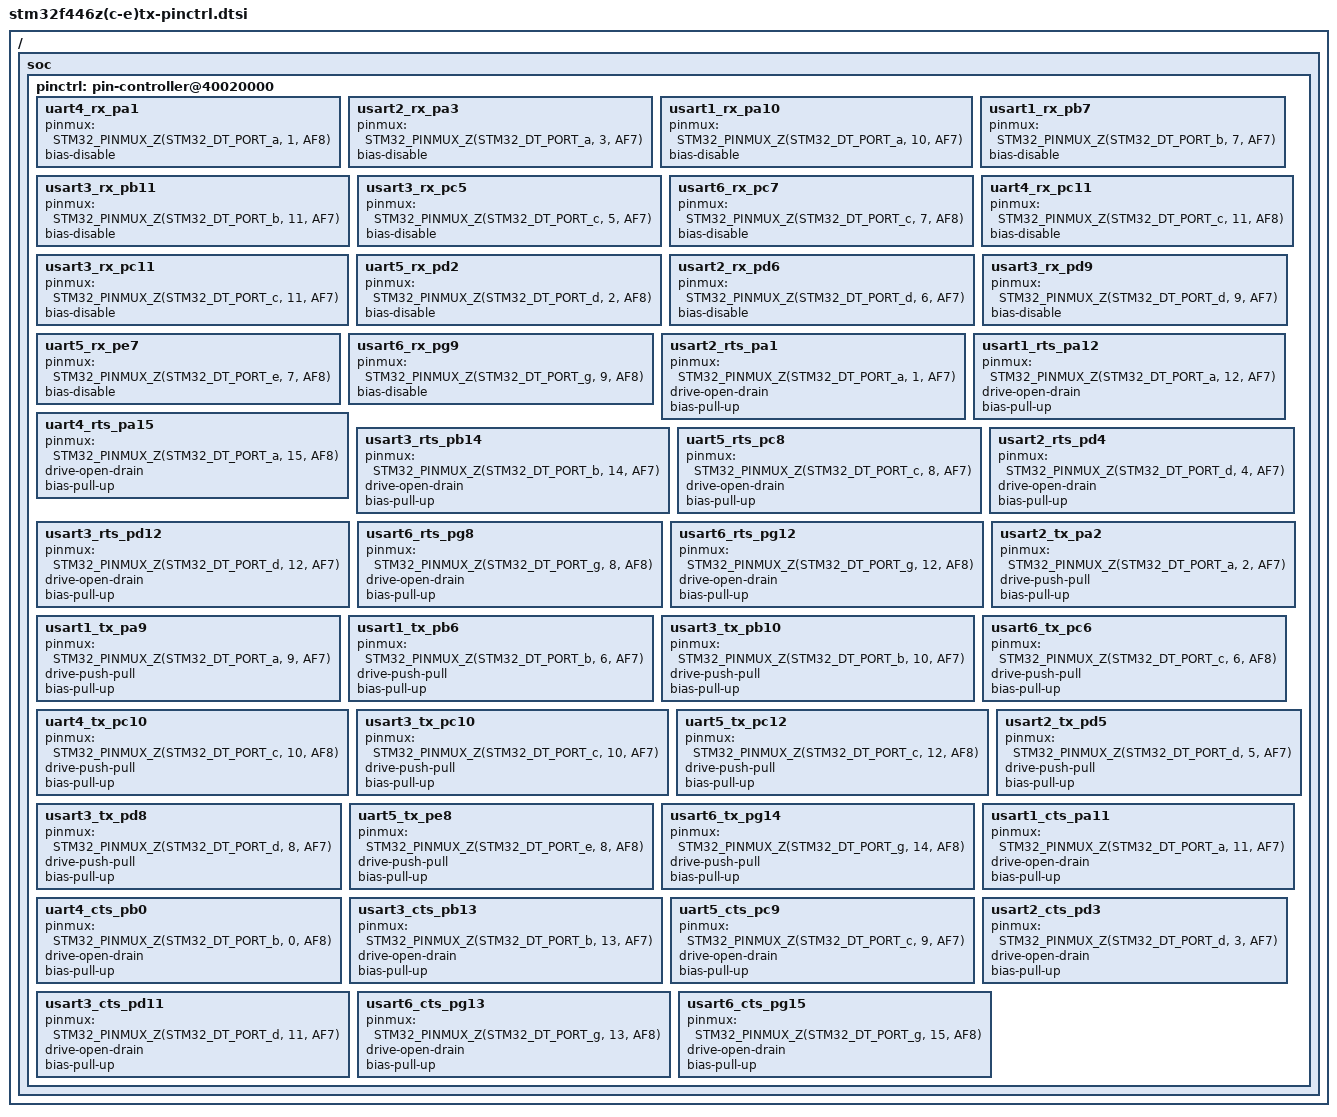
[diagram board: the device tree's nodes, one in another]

/*
 * NOTE: Autogenerated file using stm32_pinctrl_gen.py
 *
 * SPDX-License-Identifier: Apache-2.0
 */

#include <dt-bindings/pinctrl/stm32-pinctrl.h>

/ {
	soc {
		pinctrl: pin-controller@40020000 {
			/* UART_RX */
			uart4_rx_pa1: uart4_rx_pa1 {
				pinmux = <STM32_PINMUX_Z(STM32_DT_PORT_a, 1, AF8)>;
				bias-disable;
			};

			usart2_rx_pa3: usart2_rx_pa3 {
				pinmux = <STM32_PINMUX_Z(STM32_DT_PORT_a, 3, AF7)>;
				bias-disable;
			};

			usart1_rx_pa10: usart1_rx_pa10 {
				pinmux = <STM32_PINMUX_Z(STM32_DT_PORT_a, 10, AF7)>;
				bias-disable;
			};

			usart1_rx_pb7: usart1_rx_pb7 {
				pinmux = <STM32_PINMUX_Z(STM32_DT_PORT_b, 7, AF7)>;
				bias-disable;
			};

			usart3_rx_pb11: usart3_rx_pb11 {
				pinmux = <STM32_PINMUX_Z(STM32_DT_PORT_b, 11, AF7)>;
				bias-disable;
			};

			usart3_rx_pc5: usart3_rx_pc5 {
				pinmux = <STM32_PINMUX_Z(STM32_DT_PORT_c, 5, AF7)>;
				bias-disable;
			};

			usart6_rx_pc7: usart6_rx_pc7 {
				pinmux = <STM32_PINMUX_Z(STM32_DT_PORT_c, 7, AF8)>;
				bias-disable;
			};

			uart4_rx_pc11: uart4_rx_pc11 {
				pinmux = <STM32_PINMUX_Z(STM32_DT_PORT_c, 11, AF8)>;
				bias-disable;
			};

			usart3_rx_pc11: usart3_rx_pc11 {
				pinmux = <STM32_PINMUX_Z(STM32_DT_PORT_c, 11, AF7)>;
				bias-disable;
			};

			uart5_rx_pd2: uart5_rx_pd2 {
				pinmux = <STM32_PINMUX_Z(STM32_DT_PORT_d, 2, AF8)>;
				bias-disable;
			};

			usart2_rx_pd6: usart2_rx_pd6 {
				pinmux = <STM32_PINMUX_Z(STM32_DT_PORT_d, 6, AF7)>;
				bias-disable;
			};

			usart3_rx_pd9: usart3_rx_pd9 {
				pinmux = <STM32_PINMUX_Z(STM32_DT_PORT_d, 9, AF7)>;
				bias-disable;
			};

			uart5_rx_pe7: uart5_rx_pe7 {
				pinmux = <STM32_PINMUX_Z(STM32_DT_PORT_e, 7, AF8)>;
				bias-disable;
			};

			usart6_rx_pg9: usart6_rx_pg9 {
				pinmux = <STM32_PINMUX_Z(STM32_DT_PORT_g, 9, AF8)>;
				bias-disable;
			};


			/* UART_RTS */
			usart2_rts_pa1: usart2_rts_pa1 {
				pinmux = <STM32_PINMUX_Z(STM32_DT_PORT_a, 1, AF7)>;
				drive-open-drain;
				bias-pull-up;
			};

			usart1_rts_pa12: usart1_rts_pa12 {
				pinmux = <STM32_PINMUX_Z(STM32_DT_PORT_a, 12, AF7)>;
				drive-open-drain;
				bias-pull-up;
			};

			uart4_rts_pa15: uart4_rts_pa15 {
				pinmux = <STM32_PINMUX_Z(STM32_DT_PORT_a, 15, AF8)>;
				drive-open-drain;
				bias-pull-up;
			};

			usart3_rts_pb14: usart3_rts_pb14 {
				pinmux = <STM32_PINMUX_Z(STM32_DT_PORT_b, 14, AF7)>;
				drive-open-drain;
				bias-pull-up;
			};

			uart5_rts_pc8: uart5_rts_pc8 {
				pinmux = <STM32_PINMUX_Z(STM32_DT_PORT_c, 8, AF7)>;
				drive-open-drain;
				bias-pull-up;
			};

			usart2_rts_pd4: usart2_rts_pd4 {
				pinmux = <STM32_PINMUX_Z(STM32_DT_PORT_d, 4, AF7)>;
				drive-open-drain;
				bias-pull-up;
			};

			usart3_rts_pd12: usart3_rts_pd12 {
				pinmux = <STM32_PINMUX_Z(STM32_DT_PORT_d, 12, AF7)>;
				drive-open-drain;
				bias-pull-up;
			};

			usart6_rts_pg8: usart6_rts_pg8 {
				pinmux = <STM32_PINMUX_Z(STM32_DT_PORT_g, 8, AF8)>;
				drive-open-drain;
				bias-pull-up;
			};

			usart6_rts_pg12: usart6_rts_pg12 {
				pinmux = <STM32_PINMUX_Z(STM32_DT_PORT_g, 12, AF8)>;
				drive-open-drain;
				bias-pull-up;
			};


			/* UART_TX */
			usart2_tx_pa2: usart2_tx_pa2 {
				pinmux = <STM32_PINMUX_Z(STM32_DT_PORT_a, 2, AF7)>;
				drive-push-pull;
				bias-pull-up;
			};

			usart1_tx_pa9: usart1_tx_pa9 {
				pinmux = <STM32_PINMUX_Z(STM32_DT_PORT_a, 9, AF7)>;
				drive-push-pull;
				bias-pull-up;
			};

			usart1_tx_pb6: usart1_tx_pb6 {
				pinmux = <STM32_PINMUX_Z(STM32_DT_PORT_b, 6, AF7)>;
				drive-push-pull;
				bias-pull-up;
			};

			usart3_tx_pb10: usart3_tx_pb10 {
				pinmux = <STM32_PINMUX_Z(STM32_DT_PORT_b, 10, AF7)>;
				drive-push-pull;
				bias-pull-up;
			};

			usart6_tx_pc6: usart6_tx_pc6 {
				pinmux = <STM32_PINMUX_Z(STM32_DT_PORT_c, 6, AF8)>;
				drive-push-pull;
				bias-pull-up;
			};

			uart4_tx_pc10: uart4_tx_pc10 {
				pinmux = <STM32_PINMUX_Z(STM32_DT_PORT_c, 10, AF8)>;
				drive-push-pull;
				bias-pull-up;
			};

			usart3_tx_pc10: usart3_tx_pc10 {
				pinmux = <STM32_PINMUX_Z(STM32_DT_PORT_c, 10, AF7)>;
				drive-push-pull;
				bias-pull-up;
			};

			uart5_tx_pc12: uart5_tx_pc12 {
				pinmux = <STM32_PINMUX_Z(STM32_DT_PORT_c, 12, AF8)>;
				drive-push-pull;
				bias-pull-up;
			};

			usart2_tx_pd5: usart2_tx_pd5 {
				pinmux = <STM32_PINMUX_Z(STM32_DT_PORT_d, 5, AF7)>;
				drive-push-pull;
				bias-pull-up;
			};

			usart3_tx_pd8: usart3_tx_pd8 {
				pinmux = <STM32_PINMUX_Z(STM32_DT_PORT_d, 8, AF7)>;
				drive-push-pull;
				bias-pull-up;
			};

			uart5_tx_pe8: uart5_tx_pe8 {
				pinmux = <STM32_PINMUX_Z(STM32_DT_PORT_e, 8, AF8)>;
				drive-push-pull;
				bias-pull-up;
			};

			usart6_tx_pg14: usart6_tx_pg14 {
				pinmux = <STM32_PINMUX_Z(STM32_DT_PORT_g, 14, AF8)>;
				drive-push-pull;
				bias-pull-up;
			};


			/* UART_CTS */
			usart1_cts_pa11: usart1_cts_pa11 {
				pinmux = <STM32_PINMUX_Z(STM32_DT_PORT_a, 11, AF7)>;
				drive-open-drain;
				bias-pull-up;
			};

			uart4_cts_pb0: uart4_cts_pb0 {
				pinmux = <STM32_PINMUX_Z(STM32_DT_PORT_b, 0, AF8)>;
				drive-open-drain;
				bias-pull-up;
			};

			usart3_cts_pb13: usart3_cts_pb13 {
				pinmux = <STM32_PINMUX_Z(STM32_DT_PORT_b, 13, AF7)>;
				drive-open-drain;
				bias-pull-up;
			};

			uart5_cts_pc9: uart5_cts_pc9 {
				pinmux = <STM32_PINMUX_Z(STM32_DT_PORT_c, 9, AF7)>;
				drive-open-drain;
				bias-pull-up;
			};

			usart2_cts_pd3: usart2_cts_pd3 {
				pinmux = <STM32_PINMUX_Z(STM32_DT_PORT_d, 3, AF7)>;
				drive-open-drain;
				bias-pull-up;
			};

			usart3_cts_pd11: usart3_cts_pd11 {
				pinmux = <STM32_PINMUX_Z(STM32_DT_PORT_d, 11, AF7)>;
				drive-open-drain;
				bias-pull-up;
			};

			usart6_cts_pg13: usart6_cts_pg13 {
				pinmux = <STM32_PINMUX_Z(STM32_DT_PORT_g, 13, AF8)>;
				drive-open-drain;
				bias-pull-up;
			};

			usart6_cts_pg15: usart6_cts_pg15 {
				pinmux = <STM32_PINMUX_Z(STM32_DT_PORT_g, 15, AF8)>;
				drive-open-drain;
				bias-pull-up;
			};

		};
	};
};
